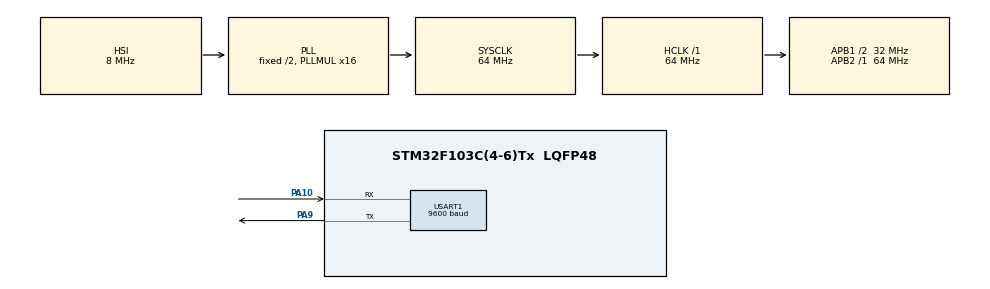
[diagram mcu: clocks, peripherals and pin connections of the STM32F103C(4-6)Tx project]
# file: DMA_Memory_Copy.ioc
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Dma.MEMTOMEM.0.Direction=DMA_MEMORY_TO_MEMORY
Dma.MEMTOMEM.0.Instance=DMA1_Channel1
Dma.MEMTOMEM.0.MemDataAlignment=DMA_MDATAALIGN_WORD
Dma.MEMTOMEM.0.MemInc=DMA_MINC_DISABLE
Dma.MEMTOMEM.0.Mode=DMA_NORMAL
Dma.MEMTOMEM.0.PeriphDataAlignment=DMA_PDATAALIGN_WORD
Dma.MEMTOMEM.0.PeriphInc=DMA_PINC_DISABLE
Dma.MEMTOMEM.0.Priority=DMA_PRIORITY_LOW
Dma.Request0=MEMTOMEM
Mcu.Family=STM32F1
Mcu.Name=STM32F103C(4-6)Tx
Mcu.Package=LQFP48
NVIC.PriorityGroup=NVIC_PRIORITYGROUP_4
NVIC.USART1_IRQn=true\:0\:0\:false\:false\:true\:true\:true
PA10.Mode=Asynchronous
PA10.Signal=USART1_RX
PA13.Mode=Serial_Wire
PA13.Signal=SYS_JTMS-SWDIO
PA14.Mode=Serial_Wire
PA14.Signal=SYS_JTCK-SWCLK
PA9.Mode=Asynchronous
PA9.Signal=USART1_TX
PC14-OSC32_IN.Mode=LSE-External-Oscillator
PC14-OSC32_IN.Signal=RCC_OSC32_IN
PC15-OSC32_OUT.Mode=LSE-External-Oscillator
PC15-OSC32_OUT.Signal=RCC_OSC32_OUT
PD0-OSC_IN.Mode=HSE-External-Oscillator
PD0-OSC_IN.Signal=RCC_OSC_IN
PD1-OSC_OUT.Mode=HSE-External-Oscillator
PD1-OSC_OUT.Signal=RCC_OSC_OUT
ProjectManager.HeapSize=0x200
ProjectManager.StackSize=0x400
ProjectManager.TargetToolchain=MDK-ARM V5
RCC.AHBFreq_Value=64000000
RCC.APB1CLKDivider=RCC_HCLK_DIV2
RCC.APB1Freq_Value=32000000
RCC.APB1TimFreq_Value=64000000
RCC.APB2Freq_Value=64000000
RCC.APB2TimFreq_Value=64000000
RCC.HCLKFreq_Value=64000000
RCC.PLLMUL=RCC_PLL_MUL16
RCC.SYSCLKFreq_VALUE=64000000
RCC.SYSCLKSource=RCC_SYSCLKSOURCE_PLLCLK
RCC.USBFreq_Value=64000000
USART1.BaudRate=9600
USART1.VirtualMode=VM_ASYNC
board=custom

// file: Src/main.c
/* USER CODE BEGIN Header */
/**
  ******************************************************************************
  * @file           : main.c
  * @brief          : Main program body
  ******************************************************************************
  * @attention
  *
  * <h2><center>&copy; Copyright (c) 2022 STMicroelectronics.
  * All rights reserved.</center></h2>
  *
  * This software component is licensed by ST under BSD 3-Clause license,
  * the "License"; You may not use this file except in compliance with the
  * License. You may obtain a copy of the License at:
  *                        opensource.org/licenses/BSD-3-Clause
  *
  ******************************************************************************
  */
/* USER CODE END Header */

#include "main.h"

UART_HandleTypeDef huart1;

DMA_HandleTypeDef hdma_memtomem_dma1_channel1;

void SystemClock_Config(void);
static void MX_GPIO_Init(void);
static void MX_DMA_Init(void);
static void MX_USART1_UART_Init(void);
/* USER CODE BEGIN PFP */
uint8_t a[1024]="fuck_you";
uint8_t b[1024];
uint32_t tickstart;
uint32_t tickend;
/* USER CODE END PFP */

int main(void)
{

  /* MCU Configuration--------------------------------------------------------*/

  /* Reset of all peripherals, Initializes the Flash interface and the Systick. */
  HAL_Init();

  /* Configure the system clock */
  SystemClock_Config();

  /* Initialize all configured peripherals */
  MX_GPIO_Init();
  MX_DMA_Init();
  MX_USART1_UART_Init();
  /* USER CODE BEGIN 2 */
	tickstart=HAL_GetTick();
	for(int i=0;i<1000;i++)
{
	HAL_DMA_Start(&hdma_memtomem_dma1_channel1,(uint32_t)a,(uint32_t)b,1024);
	HAL_DMA_PollForTransfer(&hdma_memtomem_dma1_channel1,HAL_DMA_FULL_TRANSFER,1000);
}
	tickend=HAL_GetTick();

uint8_t code[4];
code[0]=(uint8_t)(tickend-tickstart)>>24;
code[1]=(uint8_t)(tickend-tickstart)>>18&0xFF;
code[2]=(uint8_t)(tickend-tickstart)>>12&0xFF;
code[3]=(uint8_t)(tickend-tickstart)&0xFF;
HAL_UART_Transmit(&huart1,code,4,100);

  /* USER CODE END 2 */

  /* Infinite loop */
  while (1)
  {

  }
}

void SystemClock_Config(void)
{
  RCC_OscInitTypeDef RCC_OscInitStruct = {0};
  RCC_ClkInitTypeDef RCC_ClkInitStruct = {0};

  /** Initializes the CPU, AHB and APB busses clocks
  */
  RCC_OscInitStruct.OscillatorType = RCC_OSCILLATORTYPE_HSI;
  RCC_OscInitStruct.HSIState = RCC_HSI_ON;
  RCC_OscInitStruct.HSICalibrationValue = RCC_HSICALIBRATION_DEFAULT;
  RCC_OscInitStruct.PLL.PLLState = RCC_PLL_ON;
  RCC_OscInitStruct.PLL.PLLSource = RCC_PLLSOURCE_HSI_DIV2;
  RCC_OscInitStruct.PLL.PLLMUL = RCC_PLL_MUL16;
  if (HAL_RCC_OscConfig(&RCC_OscInitStruct) != HAL_OK)
  {
    Error_Handler();
  }
  /** Initializes the CPU, AHB and APB busses clocks
  */
  RCC_ClkInitStruct.ClockType = RCC_CLOCKTYPE_HCLK|RCC_CLOCKTYPE_SYSCLK
                              |RCC_CLOCKTYPE_PCLK1|RCC_CLOCKTYPE_PCLK2;
  RCC_ClkInitStruct.SYSCLKSource = RCC_SYSCLKSOURCE_PLLCLK;
  RCC_ClkInitStruct.AHBCLKDivider = RCC_SYSCLK_DIV1;
  RCC_ClkInitStruct.APB1CLKDivider = RCC_HCLK_DIV2;
  RCC_ClkInitStruct.APB2CLKDivider = RCC_HCLK_DIV1;

  if (HAL_RCC_ClockConfig(&RCC_ClkInitStruct, FLASH_LATENCY_2) != HAL_OK)
  {
    Error_Handler();
  }
}

static void MX_USART1_UART_Init(void)
{

  huart1.Instance = USART1;
  huart1.Init.BaudRate = 9600;
  huart1.Init.WordLength = UART_WORDLENGTH_8B;
  huart1.Init.StopBits = UART_STOPBITS_1;
  huart1.Init.Parity = UART_PARITY_NONE;
  huart1.Init.Mode = UART_MODE_TX_RX;
  huart1.Init.HwFlowCtl = UART_HWCONTROL_NONE;
  huart1.Init.OverSampling = UART_OVERSAMPLING_16;
  if (HAL_UART_Init(&huart1) != HAL_OK)
  {
    Error_Handler();
  }

}

static void MX_DMA_Init(void)
{

  /* DMA controller clock enable */
  __HAL_RCC_DMA1_CLK_ENABLE();

  /* Configure DMA request hdma_memtomem_dma1_channel1 on DMA1_Channel1 */
  hdma_memtomem_dma1_channel1.Instance = DMA1_Channel1;
  hdma_memtomem_dma1_channel1.Init.Direction = DMA_MEMORY_TO_MEMORY;
  hdma_memtomem_dma1_channel1.Init.PeriphInc = DMA_PINC_DISABLE;
  hdma_memtomem_dma1_channel1.Init.MemInc = DMA_MINC_DISABLE;
  hdma_memtomem_dma1_channel1.Init.PeriphDataAlignment = DMA_PDATAALIGN_WORD;
  hdma_memtomem_dma1_channel1.Init.MemDataAlignment = DMA_MDATAALIGN_WORD;
  hdma_memtomem_dma1_channel1.Init.Mode = DMA_NORMAL;
  hdma_memtomem_dma1_channel1.Init.Priority = DMA_PRIORITY_LOW;
  if (HAL_DMA_Init(&hdma_memtomem_dma1_channel1) != HAL_OK)
  {
    Error_Handler( );
  }

}

static void MX_GPIO_Init(void)
{

  /* GPIO Ports Clock Enable */
  __HAL_RCC_GPIOC_CLK_ENABLE();
  __HAL_RCC_GPIOD_CLK_ENABLE();
  __HAL_RCC_GPIOA_CLK_ENABLE();

}

void Error_Handler(void)
{
}

/************************ (C) COPYRIGHT STMicroelectronics *****END OF FILE****/
